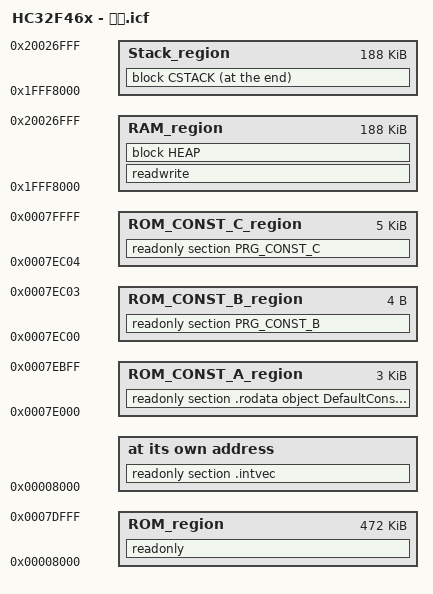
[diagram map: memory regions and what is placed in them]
/*###ICF### Section handled by ICF editor, don't touch! ****/
/*-Editor annotation file-*/
/* IcfEditorFile="$TOOLKIT_DIR$\config\ide\IcfEditor\cortex_v1_4.xml" */
/*-Specials-*/
define symbol __ICFEDIT_intvec_start__ = 0x00008000;
/*-Memory Regions-*/
define symbol __ICFEDIT_region_IROM1_start__ = 0x00008000;
define symbol __ICFEDIT_region_IROM1_end__   = 0x0007DFFF;  // т╓аТ8K
define symbol __ICFEDIT_region_IROM2_start__ = 0x0007E000;
define symbol __ICFEDIT_region_IROM2_end__   = 0x0007EBFF;
define symbol __ICFEDIT_region_IROM3_start__ = 0x0007EC00;
define symbol __ICFEDIT_region_IROM3_end__   = 0x0007EC03;
define symbol __ICFEDIT_region_IROM4_start__ = 0x0007EC04;
define symbol __ICFEDIT_region_IROM4_end__   = 0x0007FFFF;

/*
define symbol __ICFEDIT_region_EROM1_start__ = 0x0;
define symbol __ICFEDIT_region_EROM1_end__   = 0x0;
define symbol __ICFEDIT_region_EROM2_start__ = 0x0;
define symbol __ICFEDIT_region_EROM2_end__   = 0x0;
define symbol __ICFEDIT_region_EROM3_start__ = 0x0;
define symbol __ICFEDIT_region_EROM3_end__   = 0x0;                        */

define symbol __ICFEDIT_region_IRAM1_start__ = 0x1FFF8000;
define symbol __ICFEDIT_region_IRAM1_end__   = 0x20026FFF;

/*
define symbol __ICFEDIT_region_IRAM2_start__ = 0x20000000;
define symbol __ICFEDIT_region_IRAM2_end__   = 0x2000FFFF;
define symbol __ICFEDIT_region_IRAM3_start__ = 0x20010000;
define symbol __ICFEDIT_region_IRAM3_end__   = 0x2001FFFF;
define symbol __ICFEDIT_region_IRAM4_start__ = 0x20020000;
define symbol __ICFEDIT_region_IRAM4_end__   = 0x20026FFF;
define symbol __ICFEDIT_region_IRAM5_start__ = 0x200F0000;
define symbol __ICFEDIT_region_IRAM5_end__   = 0x200F0FFF;
*/

define symbol __ICFEDIT_region_ERAM1_start__ = 0x0;
define symbol __ICFEDIT_region_ERAM1_end__   = 0x0;
define symbol __ICFEDIT_region_ERAM2_start__ = 0x0;
define symbol __ICFEDIT_region_ERAM2_end__   = 0x0;
define symbol __ICFEDIT_region_ERAM3_start__ = 0x0;
define symbol __ICFEDIT_region_ERAM3_end__   = 0x0;

/*-Sizes-*/
define symbol __ICFEDIT_size_cstack__     = 0x2AF8;
define symbol __ICFEDIT_size_proc_stack__ = 0x0;
define symbol __ICFEDIT_size_heap__       = 0x200;
/**** End of ICF editor section. ###ICF###*/

define memory mem with size = 4G;
define region ROM_region			=   mem:[from __ICFEDIT_region_IROM1_start__   to __ICFEDIT_region_IROM1_end__];
define region ROM_CONST_A_region	=   mem:[from __ICFEDIT_region_IROM2_start__  to __ICFEDIT_region_IROM2_end__];
define region ROM_CONST_B_region  	=   mem:[from __ICFEDIT_region_IROM3_start__  to __ICFEDIT_region_IROM3_end__];
define region ROM_CONST_C_region  	=   mem:[from __ICFEDIT_region_IROM4_start__  to __ICFEDIT_region_IROM4_end__];

define region RAM_region       =   mem:[from __ICFEDIT_region_IRAM1_start__   to __ICFEDIT_region_IRAM1_end__];
 			/*| mem:[from __ICFEDIT_region_IRAM2_start__   to __ICFEDIT_region_IRAM2_end__]
                                	| mem:[from __ICFEDIT_region_IRAM3_start__   to __ICFEDIT_region_IRAM3_end__]
			| mem:[from __ICFEDIT_region_IRAM4_start__   to __ICFEDIT_region_IRAM4_end__];*/	
			/*| mem:[from __ICFEDIT_region_IRAM5_start__   to __ICFEDIT_region_IRAM5_end__];	*/	
/*define region RAM_Mid       =   mem:[from __ICFEDIT_region_IRAM2_start__   to __ICFEDIT_region_IRAM2_end__];
define region RAM_Exd       =   mem:[from __ICFEDIT_region_IRAM3_start__   to __ICFEDIT_region_IRAM3_end__];*/
define region Stack_region     =   mem:[from __ICFEDIT_region_IRAM1_start__   to __ICFEDIT_region_IRAM1_end__];
/*                                 | mem:[from __ICFEDIT_region_IRAM4_start__   to __ICFEDIT_region_IRAM4_end__]
                                 | mem:[from __ICFEDIT_region_IRAM5_start__   to __ICFEDIT_region_IRAM5_end__];
*/
define block CSTACK    with alignment = 8, size = __ICFEDIT_size_cstack__   { };
define block HEAP      with alignment = 8, size = __ICFEDIT_size_heap__     { };

initialize by copy { readwrite };
do not initialize  { section .noinit };

place at address mem:__ICFEDIT_intvec_start__ { readonly section .intvec };

place in ROM_CONST_A_region  {readonly section .rodata object DefaultConstPara_3Phase.o};
// place in ROM_CONST_A_region  {readonly section PRG_CONST_A};
place in ROM_CONST_B_region  {readonly section PRG_CONST_B};
place in ROM_CONST_C_region  {readonly section PRG_CONST_C};
/*place in ROM_CODE_A_region  {readonly section PRG_CODE_A};*/
/*
place in ROM_Mid {readonly section .rodata object mid.lib};
place in ROM_Mid {readonly section .text object mid.lib};
place in ROM_Exd {readonly section .rodata object ModuleA.lib};
place in ROM_Exd {readonly section .text  object ModuleA.lib};
*/
place in ROM_region   { readonly };

place in RAM_region   { readwrite, block HEAP };
/*
place in RAM_Mid	{readwrite section .data object mid.lib};
place in RAM_Mid	{readwrite section .bss object mid.lib};
place in RAM_Exd 	{readwrite section .data object ModuleA.lib};
place in RAM_Exd 	{readwrite section .bss object ModuleA.lib};
*/
place at end of Stack_region   {block CSTACK};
